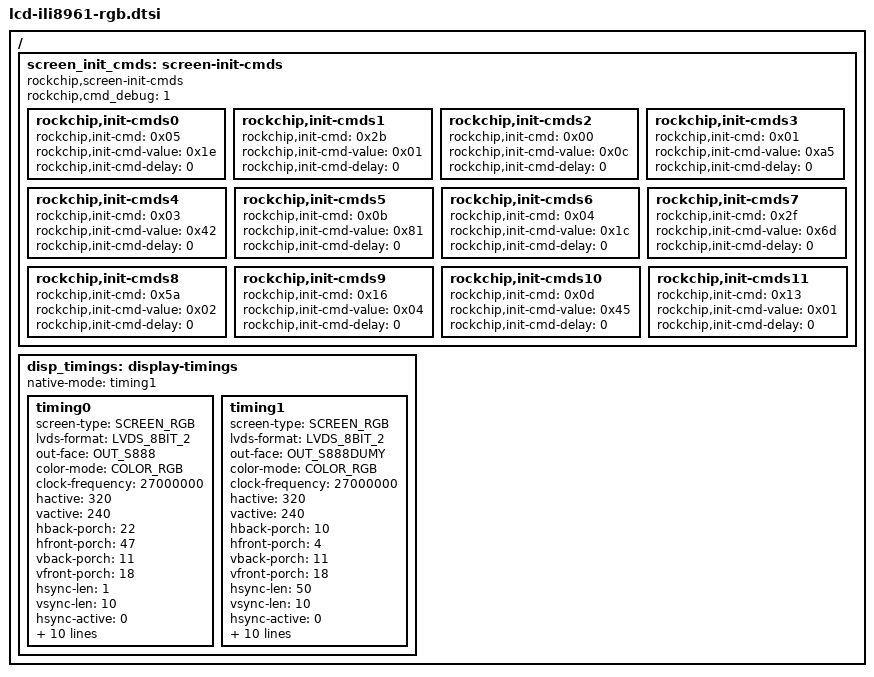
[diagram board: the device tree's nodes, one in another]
/*
 * Copyright (c) 2016 Fuzhou Rockchip Electronics Co., Ltd
 *
 * This file is dual-licensed: you can use it either under the terms
 * of the GPL or the X11 license, at your option. Note that this dual
 * licensing only applies to this file, and not this project as a
 * whole.
 *
 *  a) This library is free software; you can redistribute it and/or
 *     modify it under the terms of the GNU General Public License as
 *     published by the Free Software Foundation; either version 2 of the
 *     License, or (at your option) any later version.
 *
 *     This library is distributed in the hope that it will be useful,
 *     but WITHOUT ANY WARRANTY; without even the implied warranty of
 *     MERCHANTABILITY or FITNESS FOR A PARTICULAR PURPOSE.  See the
 *     GNU General Public License for more details.
 *
 * Or, alternatively,
 *
 *  b) Permission is hereby granted, free of charge, to any person
 *     obtaining a copy of this software and associated documentation
 *     files (the "Software"), to deal in the Software without
 *     restriction, including without limitation the rights to use,
 *     copy, modify, merge, publish, distribute, sublicense, and/or
 *     sell copies of the Software, and to permit persons to whom the
 *     Software is furnished to do so, subject to the following
 *     conditions:
 *
 *     The above copyright notice and this permission notice shall be
 *     included in all copies or substantial portions of the Software.
 *
 *     THE SOFTWARE IS PROVIDED "AS IS", WITHOUT WARRANTY OF ANY KIND,
 *     EXPRESS OR IMPLIED, INCLUDING BUT NOT LIMITED TO THE WARRANTIES
 *     OF MERCHANTABILITY, FITNESS FOR A PARTICULAR PURPOSE AND
 *     NONINFRINGEMENT. IN NO EVENT SHALL THE AUTHORS OR COPYRIGHT
 *     HOLDERS BE LIABLE FOR ANY CLAIM, DAMAGES OR OTHER LIABILITY,
 *     WHETHER IN AN ACTION OF CONTRACT, TORT OR OTHERWISE, ARISING
 *     FROM, OUT OF OR IN CONNECTION WITH THE SOFTWARE OR THE USE OR
 *     OTHER DEALINGS IN THE SOFTWARE.
 */
/{
	screen_init_cmds: screen-init-cmds {
		compatible = "rockchip,screen-init-cmds";
		rockchip,cmd_debug = <1>;

		rockchip,init-cmds0 {
			rockchip,init-cmd = <0x05>;
			rockchip,init-cmd-value = <0x1e>;
			rockchip,init-cmd-delay = <0>;
		};

		rockchip,init-cmds1 {
			rockchip,init-cmd = <0x2b>;
			rockchip,init-cmd-value = <0x01>;
			rockchip,init-cmd-delay = <0>;
		};

		rockchip,init-cmds2 {
			rockchip,init-cmd = <0x00>;
			rockchip,init-cmd-value = <0x0c>;
			rockchip,init-cmd-delay = <0>;
		};

		rockchip,init-cmds3 {
			rockchip,init-cmd = <0x01>;
			rockchip,init-cmd-value = <0xa5>;
			rockchip,init-cmd-delay = <0>;
		};

		rockchip,init-cmds4 {
			rockchip,init-cmd = <0x03>;
			rockchip,init-cmd-value = <0x42>;
			rockchip,init-cmd-delay = <0>;
		};

		rockchip,init-cmds5 {
			rockchip,init-cmd = <0x0b>;
			rockchip,init-cmd-value = <0x81>;
			rockchip,init-cmd-delay = <0>;
		};

		#if 0 /* srgb */
		rockchip,init-cmds6 {
			rockchip,init-cmd = <0x04>;
			rockchip,init-cmd-value = <0x0c>;
			rockchip,init-cmd-delay = <0>;
		};
		#else /* srgb dummy */
		rockchip,init-cmds6 {
			rockchip,init-cmd = <0x04>;
			rockchip,init-cmd-value = <0x1c>;
			rockchip,init-cmd-delay = <0>;
		};
		#endif

		rockchip,init-cmds7 {
			rockchip,init-cmd = <0x2f>;
			rockchip,init-cmd-value = <0x6d>;
			rockchip,init-cmd-delay = <0>;
		};

		rockchip,init-cmds8 {
			rockchip,init-cmd = <0x5a>;
			rockchip,init-cmd-value = <0x02>;
			rockchip,init-cmd-delay = <0>;
		};

		rockchip,init-cmds9 {
			rockchip,init-cmd = <0x16>;
			rockchip,init-cmd-value = <0x04>;
			rockchip,init-cmd-delay = <0>;
		};

		rockchip,init-cmds10 {
			rockchip,init-cmd = <0x0d>;
			rockchip,init-cmd-value = <0x45>;
			rockchip,init-cmd-delay = <0>;
		};
		/* line 2nd: rgb->gbr */
		rockchip,init-cmds11 {
			rockchip,init-cmd = <0x13>;
			rockchip,init-cmd-value = <0x01>;
			rockchip,init-cmd-delay = <0>;
		};
	};

	disp_timings: display-timings {
		native-mode = <&timing1>;
		timing0: timing0 {
			screen-type = <SCREEN_RGB>;
			lvds-format = <LVDS_8BIT_2>;
			out-face    = <OUT_S888>;
			color-mode = <COLOR_RGB>;
			clock-frequency = <27000000>;
			hactive = <320>;
			vactive = <240>;
			hback-porch = <22>;
			hfront-porch = <47>;
			vback-porch = <11>;
			vfront-porch = <18>;
			hsync-len = <1>;
			vsync-len = <10>;
			hsync-active = <0>;
			vsync-active = <0>;
			de-active = <0>;
			pixelclk-active = <1>;
			swap-rb = <0>;
			swap-rg = <1>;
			swap-gb = <0>;
			swap-delta = <0>;
			swap-dummy = <0>;
			screen-width = <37>;
			screen-hight = <66>;
		};
		timing1: timing1 {
			screen-type = <SCREEN_RGB>;
			lvds-format = <LVDS_8BIT_2>;
			out-face    = <OUT_S888DUMY>;
			color-mode = <COLOR_RGB>;
			clock-frequency = <27000000>;
			hactive = <320>;
			vactive = <240>;
			hback-porch = <10>;
			hfront-porch = <4>;
			vback-porch = <11>;
			vfront-porch = <18>;
			hsync-len = <50>;
			vsync-len = <10>;
			hsync-active = <0>;
			vsync-active = <0>;
			de-active = <0>;
			pixelclk-active = <1>;
			swap-rb = <1>;
			swap-rg = <0>;
			swap-gb = <0>;
			swap-delta = <0>;
			swap-dummy = <1>;
			screen-width = <37>;
			screen-hight = <66>;
		};
	};
};
